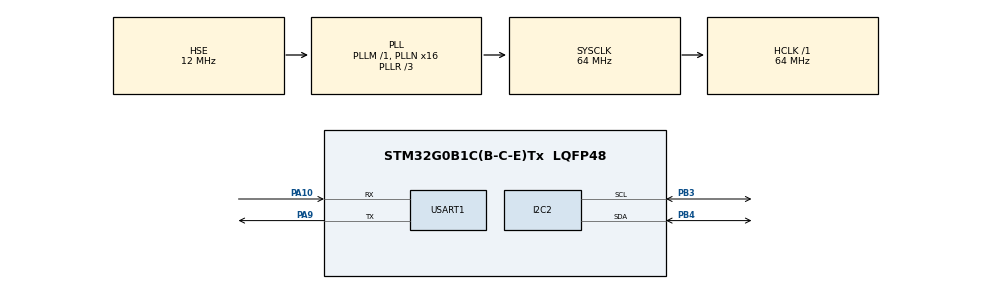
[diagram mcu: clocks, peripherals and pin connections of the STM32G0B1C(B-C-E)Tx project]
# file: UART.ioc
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Dma.Request0=USART1_RX
Dma.Request1=USART1_TX
Dma.USART1_RX.0.Direction=DMA_PERIPH_TO_MEMORY
Dma.USART1_RX.0.EventEnable=DISABLE
Dma.USART1_RX.0.Instance=DMA1_Channel1
Dma.USART1_RX.0.MemDataAlignment=DMA_MDATAALIGN_BYTE
Dma.USART1_RX.0.MemInc=DMA_MINC_ENABLE
Dma.USART1_RX.0.Mode=DMA_NORMAL
Dma.USART1_RX.0.PeriphDataAlignment=DMA_PDATAALIGN_BYTE
Dma.USART1_RX.0.PeriphInc=DMA_PINC_DISABLE
Dma.USART1_RX.0.Polarity=HAL_DMAMUX_REQ_GEN_RISING
Dma.USART1_RX.0.Priority=DMA_PRIORITY_LOW
Dma.USART1_RX.0.RequestNumber=1
Dma.USART1_RX.0.SignalID=NONE
Dma.USART1_RX.0.SyncEnable=DISABLE
Dma.USART1_RX.0.SyncPolarity=HAL_DMAMUX_SYNC_NO_EVENT
Dma.USART1_RX.0.SyncRequestNumber=1
Dma.USART1_RX.0.SyncSignalID=NONE
Dma.USART1_TX.1.Direction=DMA_MEMORY_TO_PERIPH
Dma.USART1_TX.1.EventEnable=DISABLE
Dma.USART1_TX.1.Instance=DMA1_Channel2
Dma.USART1_TX.1.MemDataAlignment=DMA_MDATAALIGN_BYTE
Dma.USART1_TX.1.MemInc=DMA_MINC_ENABLE
Dma.USART1_TX.1.Mode=DMA_NORMAL
Dma.USART1_TX.1.PeriphDataAlignment=DMA_PDATAALIGN_BYTE
Dma.USART1_TX.1.PeriphInc=DMA_PINC_DISABLE
Dma.USART1_TX.1.Polarity=HAL_DMAMUX_REQ_GEN_RISING
Dma.USART1_TX.1.Priority=DMA_PRIORITY_LOW
Dma.USART1_TX.1.RequestNumber=1
Dma.USART1_TX.1.SignalID=NONE
Dma.USART1_TX.1.SyncEnable=DISABLE
Dma.USART1_TX.1.SyncPolarity=HAL_DMAMUX_SYNC_NO_EVENT
Dma.USART1_TX.1.SyncRequestNumber=1
Dma.USART1_TX.1.SyncSignalID=NONE
I2C2.Timing=0x10B17DB5
Mcu.Family=STM32G0
Mcu.Name=STM32G0B1C(B-C-E)Tx
Mcu.Package=LQFP48
NVIC.DMA1_Channel1_IRQn=true\:0\:0\:false\:false\:true\:false\:true\:true
NVIC.DMA1_Channel2_3_IRQn=true\:0\:0\:false\:false\:true\:false\:true\:true
NVIC.USART1_IRQn=true\:0\:0\:false\:false\:true\:false\:true\:true
PA10.Mode=Asynchronous
PA10.Signal=USART1_RX
PA9.Mode=Asynchronous
PA9.Signal=USART1_TX
PB3.Mode=I2C
PB3.Signal=I2C2_SCL
PB4.Mode=I2C
PB4.Signal=I2C2_SDA
PF0-OSC_IN\ (PF0).Mode=HSE-External-Oscillator
PF0-OSC_IN\ (PF0).Signal=RCC_OSC_IN
PF1-OSC_OUT\ (PF1).Mode=HSE-External-Oscillator
PF1-OSC_OUT\ (PF1).Signal=RCC_OSC_OUT
ProjectManager.HeapSize=0x200
ProjectManager.StackSize=0x400
ProjectManager.TargetToolchain=MDK-ARM V5.32
RCC.ADCFreq_Value=64000000
RCC.AHBFreq_Value=64000000
RCC.CortexFreq_Value=64000000
RCC.EXTERNAL_CLOCK_VALUE=48000
RCC.HCLKFreq_Value=64000000
RCC.HSE_VALUE=12000000
RCC.HSI48_VALUE=48000000
RCC.HSI_VALUE=16000000
RCC.LSE_VALUE=32768
RCC.PLLN=16
RCC.PLLR=RCC_PLLR_DIV3
RCC.PLLSourceVirtual=RCC_PLLSOURCE_HSE
RCC.SYSCLKFreq_VALUE=64000000
RCC.SYSCLKSource=RCC_SYSCLKSOURCE_PLLCLK
RCC.USBFreq_Value=48000000
RCC.VCOOutputFreq_Value=192000000
USART1.VirtualMode-Asynchronous=VM_ASYNC
VP_SYS_VS_DBSignals.Mode=DisableDeadBatterySignals
board=custom

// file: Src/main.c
/* USER CODE BEGIN Header */
/**
  ******************************************************************************
  * @file           : main.c
  * @brief          : Main program body
  ******************************************************************************
  * @attention
  *
  * Copyright (c) 2024 STMicroelectronics.
  * All rights reserved.
  *
  * This software is licensed under terms that can be found in the LICENSE file
  * in the root directory of this software component.
  * If no LICENSE file comes with this software, it is provided AS-IS.
  *
  ******************************************************************************
  */
/* USER CODE END Header */
#include "main.h"
#include "dma.h"
#include "i2c.h"
#include "usart.h"
#include "gpio.h"
#include "esp8266.h"
#include "oled.h"
#include <string.h>

void SystemClock_Config(void);

int main(void)
{

  /* USER CODE BEGIN 1 */

	uint8_t Senbuff[] = "AT\r\n";  //定义数据发送数组
	uint8_t cmd[] = "AT+CWMODE=1\r\n";
	uint8_t rst[] = "AT+RST\r\n";
	uint8_t wifi[] = "AT+CWJAP=\"Xiaomi Pad 5 Pro\",\"11111111\"\r\n";
	uint8_t heartbeat[] = "working\r\n";
	uint8_t ssid[] = "xiaomi";
  /* USER CODE END 1 */

  /* MCU Configuration--------------------------------------------------------*/

  /* Reset of all peripherals, Initializes the Flash interface and the Systick. */
  HAL_Init();

  /* Configure the system clock */
  SystemClock_Config();

  /* Initialize all configured peripherals */
  MX_GPIO_Init();
  MX_DMA_Init();
  MX_USART1_UART_Init();
  MX_I2C2_Init();

  /* USER CODE BEGIN 2 */
	//ESP8266_Init(&huart1);
	//Send_AT_Command(&huart1);
//	printf("Link\n");
////
		OLED_Init();
  	OLED_Clear();
		//ESP8266_SendCmd((uint8_t *)cmd,"OK");
		//OLED_ShowString(0,0,"Wifi: ",16);
		//HAL_UART_Transmit(&huart1,(uint8_t *)cmd, strlen((uint8_t *)cmd),HAL_MAX_DELAY);
		//link();
		ESP8266_Init("Xiaomi Pad 5 Pro","11111111");
//	OLED_ShowString(0,0,"Wifi: ",16);
//	OLED_ShowString(48,0,ssid,16);

	 //OLED_Display_On();
	//OLED_Reverse();
	//OLED_Update();

  /*延时3000ms，观察现象*/
  //HAL_Delay(3000);

  /* USER CODE END 2 */
  /* Infinite loop */
  while (1)
  {
	//HAL_UART_Transmit_DMA(&huart1, (uint8_t *)heartbeat, sizeof(heartbeat));
//		OLED_Clear();
//		OLED_Update();
		//printf("TEST\n");
		//HAL_UART_Transmit(&huart1, (uint8_t *)rst, sizeof(rst),0xff);
		//HAL_Delay(3000);
		//HAL_UART_Transmit(&huart1, (uint8_t *)cmd, sizeof(cmd),0xff);
		HAL_Delay(3000);
		//HAL_UART_Transmit(&huart1,(uint8_t *)"AT",sizeof("AT"),0xff);
		//HAL_UART_Transmit(&huart1,(uint8_t *)"AT\r\n",sizeof("AT\r\n"),0xff);

	//OLED_ShowStr(0,0,"wifi",48);
  }
}
//void HAL_UART_RxCpltCallback(UART_HandleTypeDef *huart1)
//{
//		if (__HAL_UART_GET_FLAG(huart1, UART_FLAG_RXNE) != RESET)
//    {
//        esp8266_cnt = 1;
//				if (esp8266_cnt >= sizeof(esp8266_buf))
//        {
//            esp8266_cnt = 0; // 防止缓冲区溢出
//        }

//        // 使用HAL库接收单个字节
//        uint8_t data;
//        if (HAL_OK == HAL_UART_Receive_IT(huart1, &data, 1))
//        {
//            esp8266_buf[esp8266_cnt++] = data;
//        }
//				//OLED_ShowString(0,0,(uint8_t *)esp8266_buf,8);
//        // 清除接收中断标志
//        __HAL_UART_CLEAR_FLAG(huart1, UART_FLAG_RXNE);
////				HAL_UART_Receive_IT(&huart1, (uint8_t *)&aRxBuffer, 1);   //再开启接收中断
//    }
//		OLED_ShowString(0,0,(uint8_t *)esp8266_buf,8);

//}

//void HAL_UART_RxCpltCallback(UART_HandleTypeDef *huart)
//{
//  /* Prevent unused argument(s) compilation warning */
//  UNUSED(huart);
//  /* NOTE: This function Should not be modified, when the callback is needed,
//           the HAL_UART_TxCpltCallback could be implemented in the user file5 p9 }1 L8 U' {) R; `1 o# J
//   */
//				Uart1_Rx_Cnt++;
//        if(Uart1_Rx_Cnt >= sizeof(RxBuffer))  //溢出判断
//        {
//                Uart1_Rx_Cnt = 0;
//                memset(RxBuffer,0x00,sizeof(RxBuffer));
//                //HAL_UART_Transmit(&huart1, (uint8_t *)"数据溢出", 10,0xFFFF);
//
//        }
//        else
//        {
//                RxBuffer[Uart1_Rx_Cnt-1] = aRxBuffer;   //接收数据转存
//
//                if((RxBuffer[Uart1_Rx_Cnt-2] == 'K')&&(RxBuffer[Uart1_Rx_Cnt-3] == 'O')) //判断结束位
//								{
////												//Uart1_Rx_Cnt = 1;
////												//OLED_ShowString(0,0,(uint8_t *)RxBuffer,8);
////                        HAL_UART_Transmit(&huart1, (uint8_t *)&RxBuffer, Uart1_Rx_Cnt,0xFFFF); //将收到的信息发送出去
////												//OLED_Clear();
//												OLED_ShowString(0,0,(uint8_t *)RxBuffer,8);
////												//OLED_ShowNum(0,0,i,3,16);
////										   //while(HAL_UART_GetState(&huart1) == HAL_UART_STATE_BUSY_TX);//检测UART发送结束
//                        //Uart1_Rx_Cnt = 0;
//                        //memset(RxBuffer,0x00,sizeof(RxBuffer)); //清空数组
//                }
//
//
//
//
//        }
//				OLED_ShowNum(0,4,Uart1_Rx_Cnt,3,8);
//        HAL_UART_Receive_IT(&huart1, (uint8_t *)&aRxBuffer, 1);   //再开启接收中断
//				//OLED_ShowNum(0,0,Uart1_Rx_Cnt,3,16);
//				//OLED_Clear();
//}

void SystemClock_Config(void)
{
  RCC_OscInitTypeDef RCC_OscInitStruct = {0};
  RCC_ClkInitTypeDef RCC_ClkInitStruct = {0};

  /** Configure the main internal regulator output voltage
  */
  HAL_PWREx_ControlVoltageScaling(PWR_REGULATOR_VOLTAGE_SCALE1);

  /** Initializes the RCC Oscillators according to the specified parameters
  * in the RCC_OscInitTypeDef structure.
  */
  RCC_OscInitStruct.OscillatorType = RCC_OSCILLATORTYPE_HSE;
  RCC_OscInitStruct.HSEState = RCC_HSE_ON;
  RCC_OscInitStruct.PLL.PLLState = RCC_PLL_ON;
  RCC_OscInitStruct.PLL.PLLSource = RCC_PLLSOURCE_HSE;
  RCC_OscInitStruct.PLL.PLLM = RCC_PLLM_DIV1;
  RCC_OscInitStruct.PLL.PLLN = 16;
  RCC_OscInitStruct.PLL.PLLP = RCC_PLLP_DIV2;
  RCC_OscInitStruct.PLL.PLLQ = RCC_PLLQ_DIV2;
  RCC_OscInitStruct.PLL.PLLR = RCC_PLLR_DIV3;
  if (HAL_RCC_OscConfig(&RCC_OscInitStruct) != HAL_OK)
  {
    Error_Handler();
  }

  /** Initializes the CPU, AHB and APB buses clocks
  */
  RCC_ClkInitStruct.ClockType = RCC_CLOCKTYPE_HCLK|RCC_CLOCKTYPE_SYSCLK
                              |RCC_CLOCKTYPE_PCLK1;
  RCC_ClkInitStruct.SYSCLKSource = RCC_SYSCLKSOURCE_PLLCLK;
  RCC_ClkInitStruct.AHBCLKDivider = RCC_SYSCLK_DIV1;
  RCC_ClkInitStruct.APB1CLKDivider = RCC_HCLK_DIV1;

  if (HAL_RCC_ClockConfig(&RCC_ClkInitStruct, FLASH_LATENCY_2) != HAL_OK)
  {
    Error_Handler();
  }
}

void Error_Handler(void)
{
  __disable_irq();
  while (1)
  {
  }
}
